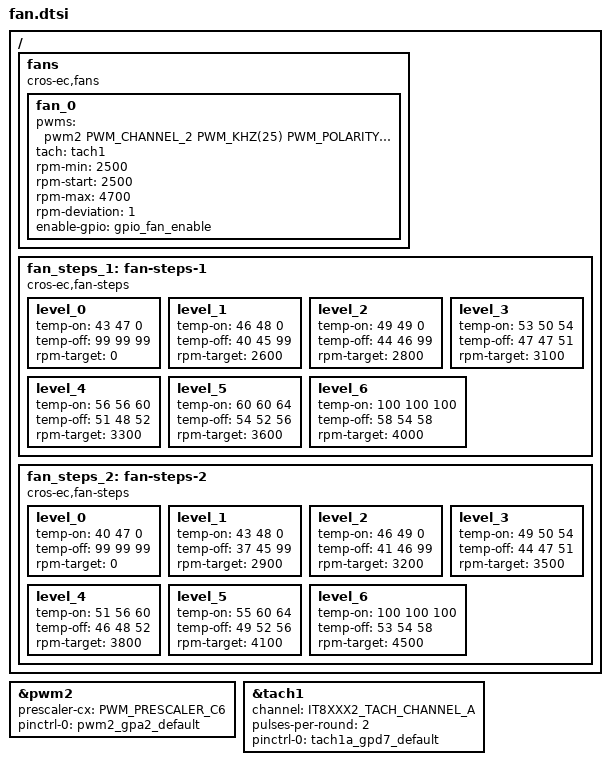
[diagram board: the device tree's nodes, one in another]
/* Copyright 2022 The ChromiumOS Authors
 * Use of this source code is governed by a BSD-style license that can be
 * found in the LICENSE file.
 */
/ {
	fans {
		compatible = "cros-ec,fans";
		fan_0 {
			pwms = <&pwm2 PWM_CHANNEL_2 PWM_KHZ(25) PWM_POLARITY_NORMAL>;
			tach = <&tach1>;
			rpm-min = <2500>;
			rpm-start = <2500>;
			rpm-max = <4700>;
			rpm-deviation = <1>;
			enable-gpio = <&gpio_fan_enable>;
		};
	};
	fan_steps_1: fan-steps-1 {
		compatible = "cros-ec,fan-steps";
		level_0 {
			temp-on = <43 47 0>;
			temp-off = <99 99 99>;
			rpm-target = <0>;
		};
		level_1 {
			temp-on = <46 48 0>;
			temp-off = <40 45 99>;
			rpm-target = <2600>;
		};
		level_2 {
			temp-on = <49 49 0>;
			temp-off = <44 46 99>;
			rpm-target = <2800>;
		};
		level_3 {
			temp-on = <53 50 54>;
			temp-off = <47 47 51>;
			rpm-target = <3100>;
		};
		level_4 {
			temp-on = <56 56 60>;
			temp-off = <51 48 52>;
			rpm-target = <3300>;
		};
		level_5 {
			temp-on = <60 60 64>;
			temp-off = <54 52 56>;
			rpm-target = <3600>;
		};
		level_6 {
			temp-on = <100 100 100>;
			temp-off = <58 54 58>;
			rpm-target = <4000>;
		};
	};
	fan_steps_2: fan-steps-2 {
		compatible = "cros-ec,fan-steps";
		level_0 {
			temp-on = <40 47 0>;
			temp-off = <99 99 99>;
			rpm-target = <0>;
		};
		level_1 {
			temp-on = <43 48 0>;
			temp-off = <37 45 99>;
			rpm-target = <2900>;
		};
		level_2 {
			temp-on = <46 49 0>;
			temp-off = <41 46 99>;
			rpm-target = <3200>;
		};
		level_3 {
			temp-on = <49 50 54>;
			temp-off = <44 47 51>;
			rpm-target = <3500>;
		};
		level_4 {
			temp-on = <51 56 60>;
			temp-off = <46 48 52>;
			rpm-target = <3800>;
		};
		level_5 {
			temp-on = <55 60 64>;
			temp-off = <49 52 56>;
			rpm-target = <4100>;
		};
		level_6 {
			temp-on = <100 100 100>;
			temp-off = <53 54 58>;
			rpm-target = <4500>;
		};
	};
};
/* pwm for fan */
&pwm2 {
	status = "okay";
	prescaler-cx = <PWM_PRESCALER_C6>;
	pinctrl-0 = <&pwm2_gpa2_default>;
	pinctrl-names = "default";
};
/* fan tachometer sensor */
&tach1 {
	status = "okay";
	channel = <IT8XXX2_TACH_CHANNEL_A>;
	pulses-per-round = <2>;
	pinctrl-0 = <&tach1a_gpd7_default>;
	pinctrl-names = "default";
};
